VERSION ""

NS_ :

BS_:

BU_: DDE EGS Vector__XXX

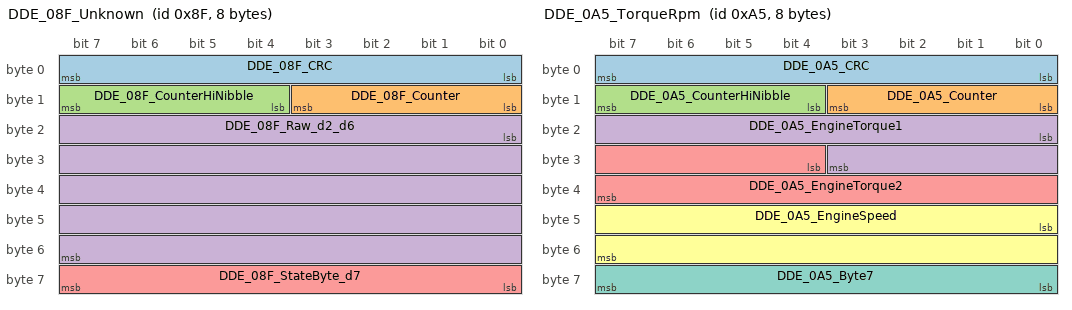
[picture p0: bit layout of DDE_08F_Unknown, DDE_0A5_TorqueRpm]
BO_ 143 DDE_08F_Unknown: 8 DDE
 SG_ DDE_08F_CRC : 0|8@1+ (1,0) [0|255] "" Vector__XXX
 SG_ DDE_08F_Counter : 8|4@1+ (1,0) [0|15] "" Vector__XXX
 SG_ DDE_08F_CounterHiNibble : 12|4@1+ (1,0) [0|15] "" Vector__XXX
 SG_ DDE_08F_Raw_d2_d6 : 16|40@1+ (1,0) [0|1099511627775] "" Vector__XXX
 SG_ DDE_08F_StateByte_d7 : 56|8@1+ (1,0) [0|255] "" Vector__XXX

BO_ 165 DDE_0A5_TorqueRpm: 8 DDE
 SG_ DDE_0A5_CRC : 0|8@1+ (1,0) [0|255] "" Vector__XXX
 SG_ DDE_0A5_Counter : 8|4@1+ (1,0) [0|15] "" Vector__XXX
 SG_ DDE_0A5_CounterHiNibble : 12|4@1+ (1,0) [0|15] "" Vector__XXX
 SG_ DDE_0A5_EngineTorque1 : 16|12@1+ (0.5,-1023.5) [-1023.5|1024] "Nm" Vector__XXX
 SG_ DDE_0A5_EngineTorque2 : 28|12@1+ (0.5,-1023.5) [-1023.5|1024] "Nm" Vector__XXX
 SG_ DDE_0A5_EngineSpeed : 40|16@1+ (0.25,0) [0|16383.75] "rpm" Vector__XXX
 SG_ DDE_0A5_Byte7 : 56|8@1+ (1,0) [0|255] "" Vector__XXX

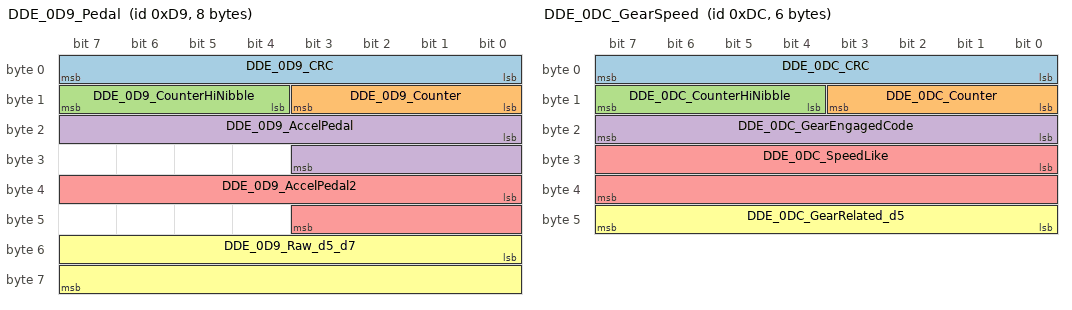
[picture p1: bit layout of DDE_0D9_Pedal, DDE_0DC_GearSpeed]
BO_ 217 DDE_0D9_Pedal: 8 DDE
 SG_ DDE_0D9_CRC : 0|8@1+ (1,0) [0|255] "" Vector__XXX
 SG_ DDE_0D9_Counter : 8|4@1+ (1,0) [0|15] "" Vector__XXX
 SG_ DDE_0D9_CounterHiNibble : 12|4@1+ (1,0) [0|15] "" Vector__XXX
 SG_ DDE_0D9_AccelPedal : 16|12@1+ (0.025,0) [0|102.375] "%" Vector__XXX
 SG_ DDE_0D9_AccelPedal2 : 32|12@1+ (0.025,0) [0|102.375] "%" Vector__XXX
 SG_ DDE_0D9_Raw_d5_d7 : 48|16@1+ (1,0) [0|65535] "" Vector__XXX

BO_ 220 DDE_0DC_GearSpeed: 6 DDE
 SG_ DDE_0DC_CRC : 0|8@1+ (1,0) [0|255] "" Vector__XXX
 SG_ DDE_0DC_Counter : 8|4@1+ (1,0) [0|15] "" Vector__XXX
 SG_ DDE_0DC_CounterHiNibble : 12|4@1+ (1,0) [0|15] "" Vector__XXX
 SG_ DDE_0DC_GearEngagedCode : 16|8@1+ (1,0) [0|255] "" Vector__XXX
 SG_ DDE_0DC_SpeedLike : 24|16@1+ (1,-2000) [-2000|63535] "raw" Vector__XXX
 SG_ DDE_0DC_GearRelated_d5 : 40|8@1+ (1,0) [0|255] "" Vector__XXX

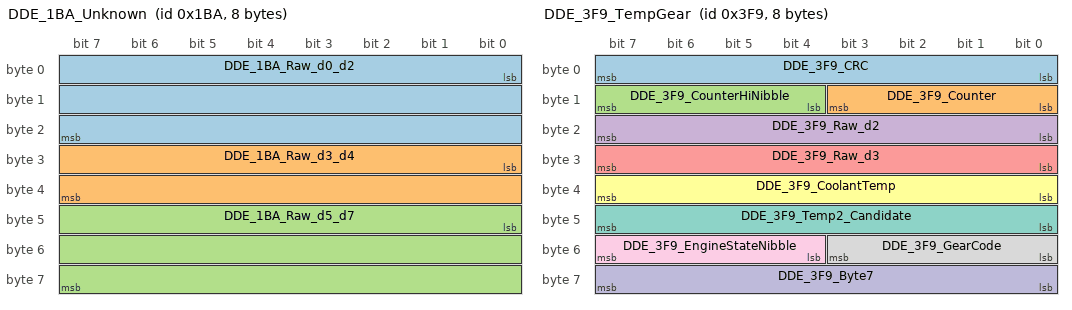
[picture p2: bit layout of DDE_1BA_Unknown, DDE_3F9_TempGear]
BO_ 442 DDE_1BA_Unknown: 8 DDE
 SG_ DDE_1BA_Raw_d0_d2 : 0|24@1+ (1,0) [0|16777215] "" Vector__XXX
 SG_ DDE_1BA_Raw_d3_d4 : 24|16@1+ (1,0) [0|65535] "" Vector__XXX
 SG_ DDE_1BA_Raw_d5_d7 : 40|24@1+ (1,0) [0|16777215] "" Vector__XXX

BO_ 1017 DDE_3F9_TempGear: 8 DDE
 SG_ DDE_3F9_CRC : 0|8@1+ (1,0) [0|255] "" Vector__XXX
 SG_ DDE_3F9_Counter : 8|4@1+ (1,0) [0|15] "" Vector__XXX
 SG_ DDE_3F9_CounterHiNibble : 12|4@1+ (1,0) [0|15] "" Vector__XXX
 SG_ DDE_3F9_Raw_d2 : 16|8@1+ (1,0) [0|255] "" Vector__XXX
 SG_ DDE_3F9_Raw_d3 : 24|8@1+ (1,0) [0|255] "" Vector__XXX
 SG_ DDE_3F9_CoolantTemp : 32|8@1+ (1,-48) [-48|207] "degC" Vector__XXX
 SG_ DDE_3F9_Temp2_Candidate : 40|8@1+ (1,-48) [-48|207] "degC" Vector__XXX
 SG_ DDE_3F9_GearCode : 48|4@1+ (1,0) [0|15] "" Vector__XXX
 SG_ DDE_3F9_EngineStateNibble : 52|4@1+ (1,0) [0|15] "" Vector__XXX
 SG_ DDE_3F9_Byte7 : 56|8@1+ (1,0) [0|255] "" Vector__XXX

BO_ 1298 DDE_512_NM: 8 DDE
 SG_ DDE_512_Raw_d0_d6 : 0|56@1+ (1,0) [0|72057594037927935] "" Vector__XXX
 SG_ DDE_512_NodeAddress : 56|8@1+ (1,0) [0|255] "" Vector__XXX

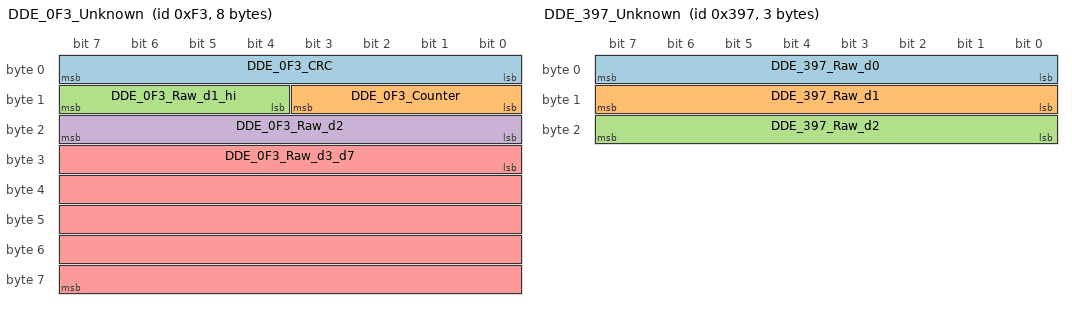
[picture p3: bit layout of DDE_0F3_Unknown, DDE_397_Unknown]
BO_ 243 DDE_0F3_Unknown: 8 DDE
 SG_ DDE_0F3_CRC : 0|8@1+ (1,0) [0|255] "" Vector__XXX
 SG_ DDE_0F3_Counter : 8|4@1+ (1,0) [0|15] "" Vector__XXX
 SG_ DDE_0F3_Raw_d1_hi : 12|4@1+ (1,0) [0|15] "" Vector__XXX
 SG_ DDE_0F3_Raw_d2 : 16|8@1+ (1,0) [0|255] "" Vector__XXX
 SG_ DDE_0F3_Raw_d3_d7 : 24|40@1+ (1,0) [0|1099511627775] "" Vector__XXX

BO_ 311 DDE_137_Unknown: 2 DDE
 SG_ DDE_137_Raw_d0 : 0|8@1+ (1,0) [0|255] "" Vector__XXX
 SG_ DDE_137_Raw_d1 : 8|8@1+ (1,0) [0|255] "" Vector__XXX

BO_ 919 DDE_397_Unknown: 3 DDE
 SG_ DDE_397_Raw_d0 : 0|8@1+ (1,0) [0|255] "" Vector__XXX
 SG_ DDE_397_Raw_d1 : 8|8@1+ (1,0) [0|255] "" Vector__XXX
 SG_ DDE_397_Raw_d2 : 16|8@1+ (1,0) [0|255] "" Vector__XXX

BO_ 947 DDE_3B3_Unknown: 7 DDE
 SG_ DDE_3B3_Raw : 0|56@1+ (1,0) [0|72057594037927935] "" Vector__XXX

BO_ 441 DDE_1B9_Unknown: 2 DDE
 SG_ DDE_1B9_Raw_d0 : 0|8@1+ (1,0) [0|255] "" Vector__XXX
 SG_ DDE_1B9_Raw_d1 : 8|8@1+ (1,0) [0|255] "" Vector__XXX

BO_ 708 DDE_2C4_Unknown: 8 DDE
 SG_ DDE_2C4_Raw_d0_d1 : 0|16@1+ (1,0) [0|65535] "" Vector__XXX
 SG_ DDE_2C4_Raw_d2_d7 : 16|48@1+ (1,0) [0|281474976710655] "" Vector__XXX

BO_ 1426 DDE_592_ServiceChannel: 8 DDE
 SG_ DDE_592_Byte0 : 0|8@1+ (1,0) [0|255] "" Vector__XXX
 SG_ DDE_592_Payload : 8|56@1+ (1,0) [0|72057594037927935] "" Vector__XXX

BO_ 641 DDE_281_Voltage: 2 DDE
 SG_ DDE_281_SupplyVoltage : 0|12@1+ (0.015,0) [0|61.425] "V" Vector__XXX
 SG_ DDE_281_Raw_d1_hi : 12|4@1+ (1,0) [0|15] "" Vector__XXX

BO_ 1019 DDE_3FB_Unknown: 6 DDE
 SG_ DDE_3FB_Raw_d0 : 0|8@1+ (1,0) [0|255] "" Vector__XXX
 SG_ DDE_3FB_Raw_d1_d5 : 8|40@1+ (1,0) [0|1099511627775] "" Vector__XXX

CM_ "BMW F11 520d (DDE EDC17C50) PT-CAN (logged as bus 3). Transmitter DDE. Built by Fred 2026-10-30 from captures ptcan1 (ignonoff, 3krev, r10md10m drive) and bench_f10 (F10 DDE alone). Byte d0 = first CAN data byte. Only signals with evidence are named; undecoded bytes are Raw_*. Cycle times are from the F11 car where present. See README.md.";
CM_ SG_ 143 DDE_08F_CRC "E2E CRC8 poly 0x1D init 0x00 xorout 0x00 over d1..d7, then XOR K=0x3C. Confirmed (see f11_dde_e2e.md).";
CM_ SG_ 143 DDE_08F_Counter "Alive counter, low nibble of d1, 0..14 (15 never used), +1 per frame, starts at 1 each wake. Confirmed.";
CM_ SG_ 143 DDE_08F_CounterHiNibble "High nibble of d1. Fixed 0x1 (0x3 briefly at crank). It is inside the CRC span, so reproduce it exactly.";
CM_ SG_ 143 DDE_08F_Raw_d2_d6 "Not decoded. LE pairs sit near 0x7D00 / 0x7CF9 in P and move in R/D.";
CM_ SG_ 143 DDE_08F_StateByte_d7 "Quasi-static enum (0x80, 0x10, 0xC0 seen). Meaning unknown.";
CM_ BO_ 143 "DDE-generated (confirmed: bench + car). Same layout and K as FlexRay 0x29 c3 group 1. On F11 PT-CAN at ~30 ms (33 Hz); PT-CAN2 10 ms. E2E K=0x3C, span d1..d7. Payload not decoded: it changes only with R/D engaged (meaning unknown).";
CM_ SG_ 165 DDE_0A5_CRC "E2E CRC8 poly 0x1D init 0x00 xorout 0x00 over d1..d7, then XOR K=0x6A. Confirmed (see f11_dde_e2e.md).";
CM_ SG_ 165 DDE_0A5_Counter "Alive counter, low nibble of d1, 0..14 (15 never used), +1 per frame, starts at 1 each wake. Confirmed.";
CM_ SG_ 165 DDE_0A5_CounterHiNibble "High nibble of d1. Fixed 0xF in the F11 car; 0xD on the F10 bench DDE. It is inside the CRC span, so reproduce it exactly.";
CM_ SG_ 165 DDE_0A5_EngineTorque1 "bits16..27. Equal to FlexRay 0x28 c1 torque field (r 0.999, slope 1.0). Scale/offset from a public hint; behaviour plausible (~232 at crank, 25..50 at idle, -35 engine off) but there is no independent torque label. Confidence: high (field), hint (unit).";
CM_ SG_ 165 DDE_0A5_EngineTorque2 "bits28..39, same format as torque 1. Role unknown. Confidence: medium.";
CM_ SG_ 165 DDE_0A5_EngineSpeed "d5..d6 LE /4. Confirmed: equal to FlexRay 0x28 c1 rpm (r 1.000), which matches OBD PID 0x0C (r 0.9998, runs 1 and 2).";
CM_ SG_ 165 DDE_0A5_Byte7 "Constant 0xF1 in all logs; inside the CRC span.";
CM_ BO_ 165 "DDE-generated (confirmed: F10 DDE-alone bench + F11 car). Same layout and K as DDE FlexRay 0x28 c1 group 1 (payload bytes 0..7), but its counters run independently of FlexRay. On F11 PT-CAN (bus 3) at 20 ms; on PT-CAN2 at 10 ms. E2E K=0x6A, span d1..d7.";
CM_ SG_ 217 DDE_0D9_CRC "E2E CRC8 poly 0x1D init 0x00 xorout 0x00 over d1..d7, then XOR K=0xD7. Confirmed (see f11_dde_e2e.md).";
CM_ SG_ 217 DDE_0D9_Counter "Alive counter, low nibble of d1, 0..14 (15 never used), +1 per frame, starts at 1 each wake. Confirmed.";
CM_ SG_ 217 DDE_0D9_CounterHiNibble "High nibble of d1. Fixed 0x1 (0x3 for ~60..80 ms at crank). It is inside the CRC span, so reproduce it exactly.";
CM_ SG_ 217 DDE_0D9_AccelPedal "bits16..27 /40. Equal to FlexRay 0x28 c1 pedal field (r 0.9998, slope 1.001). Scale from a public hint; 0 at rest, rises on throttle blips. No OBD pedal PID was logged. Confidence: high (field), hint (scale).";
CM_ SG_ 217 DDE_0D9_AccelPedal2 "bits32..43, second pedal/throttle-like value (r 0.989). Confidence: medium.";
CM_ SG_ 217 DDE_0D9_Raw_d5_d7 "Not decoded (ign-on constant e0 7f / c0 in d7).";
CM_ BO_ 217 "DDE-generated (confirmed: bench + car). Same layout and K as FlexRay 0x28 c1 group 2 (payload bytes 8..15). On F11 PT-CAN (bus 3) at 20 ms; on PT-CAN2 at 10 ms. E2E K=0xD7, span d1..d7.";
CM_ SG_ 220 DDE_0DC_CRC "E2E CRC8 poly 0x1D init 0x00 xorout 0x00 over d1..d5, then XOR K=0x0F. Confirmed (see f11_dde_e2e.md).";
CM_ SG_ 220 DDE_0DC_Counter "Alive counter, low nibble of d1, 0..14 (15 never used), +1 per frame, starts at 1 each wake. Confirmed.";
CM_ SG_ 220 DDE_0DC_CounterHiNibble "High nibble of d1. Fixed 0x1 (0x3 briefly at crank). It is inside the CRC span, so reproduce it exactly.";
CM_ SG_ 220 DDE_0DC_GearEngagedCode "d2: 0x22 = P, 0x25 = R, 0x24 = D (wake sequence 0x80 -> 0x20 -> 0x22). Confirmed against EGS 0x3FD (drive log).";
CM_ SG_ 220 DDE_0DC_SpeedLike "d3..d4 LE - 2000. Speed-like: r 0.998 vs vehicle speed 0x1A1, fitted ~7.67 raw per km/h, unsigned (positive in R). Physical unit unknown (could be a shaft speed). Confidence: medium-high.";
CM_ SG_ 220 DDE_0DC_GearRelated_d5 "d5: 0xFE in P, 0xF4 in R/D, 0xFC during park request. Confidence: medium. Inside CRC span.";
CM_ BO_ 220 "DDE-generated (confirmed: bench + car). PT-CAN only (not on PT-CAN2). Same layout and K as FlexRay 0x28 c3 group 2 (payload bytes 8..13). E2E K=0x0F, span d1..d5.";
CM_ SG_ 442 DDE_1BA_Raw_d0_d2 "Not decoded (00 00 00 at ign-on, vary when running).";
CM_ SG_ 442 DDE_1BA_Raw_d3_d4 "Not decoded LE16.";
CM_ SG_ 442 DDE_1BA_Raw_d5_d7 "Mostly constant F3 5A F0.";
CM_ BO_ 442 "DDE: sent by the F10 DDE alone on the bench, and in the F11 car its payload is identical to DDE FlexRay 0xE8 L9. Rate on bench ~1 s. CAVEAT: in the F11 car logs 0x1BA appears ONLY on PT-CAN2 (bus 2), never on PT-CAN (bus 3); it is in this file because it was requested and the bench saw it. Which physical bus the bench was wired to is not recorded beyond bus 0. No CRC/counter. Not decoded: d3..d4 LE16 varies continuously after ~5 s (ign-on value 0x2710).";
CM_ SG_ 1017 DDE_3F9_CRC "E2E CRC8 poly 0x1D init 0x00 xorout 0x00 over d1..d7, then XOR K=0x04. Confirmed (see f11_dde_e2e.md).";
CM_ SG_ 1017 DDE_3F9_Counter "Alive counter, low nibble of d1, 0..14 (15 never used), +1 per frame, starts at 1 each wake. Confirmed.";
CM_ SG_ 1017 DDE_3F9_CounterHiNibble "High nibble of d1. Fixed 0x1 (0x3 briefly at crank). Counter steps per transmission, not per time. It is inside the CRC span, so reproduce it exactly.";
CM_ SG_ 1017 DDE_3F9_Raw_d2 "Not decoded (0x80 / 0x82 seen).";
CM_ SG_ 1017 DDE_3F9_Raw_d3 "Not decoded.";
CM_ SG_ 1017 DDE_3F9_CoolantTemp "d4 - 48. Confirmed: equals FlexRay 0xE6 payload byte 4, which matches OBD PID 0x05 (r 0.997, 89.5 % exact, run 1).";
CM_ SG_ 1017 DDE_3F9_Temp2_Candidate "CANDIDATE. d5 - 48. A public hint calls it oil temperature. OBD shows it is NOT coolant (slower, lags). No independent label.";
CM_ SG_ 1017 DDE_3F9_GearCode "Low nibble of d6: 3 = P, 2 = R, 5 = D, 1 = park requested while in D. Confirmed against EGS 0x3FD gear display (drive log). N was not captured.";
CM_ SG_ 1017 DDE_3F9_EngineStateNibble "High nibble of d6: 2 = ign-on before crank, 1 = crank / after stop, 0 = running. Confidence: medium (ts run 4 and ptcan1 agree; inference from timing).";
CM_ SG_ 1017 DDE_3F9_Byte7 "Constant 0x47 in the F11 car.";
CM_ BO_ 1017 "DDE-generated (confirmed: bench + car). Same PDU as FlexRay 0xE6 L9 (same K). ~1 s plus extra frames on change. On both PT-CAN and PT-CAN2 with identical payloads. E2E K=0x04, span d1..d7.";
CM_ SG_ 1298 DDE_512_Raw_d0_d6 "Constant 00 00 00 00 FF FF 00.";
CM_ SG_ 1298 DDE_512_NodeAddress "0x12 = DDE.";
CM_ BO_ 1298 "BMW network-management frame, node 0x12 = DDE. Confirmed (bench + car, both PT-CAN and PT-CAN2). Payload 00 00 00 00 FF FF 00 12 constant in all logs. Same content as the DDE share of FlexRay 0x5C.";
CM_ SG_ 243 DDE_0F3_CRC "E2E CRC8 poly 0x1D init 0x00 xorout 0x00 over d1..d7, then XOR K=0x8F. Confirmed (see f11_dde_e2e.md).";
CM_ SG_ 243 DDE_0F3_Counter "Alive counter, low nibble of d1, 0..14 (15 never used), +1 per frame, starts at 1 each wake. Confirmed.";
CM_ SG_ 243 DDE_0F3_Raw_d1_hi "High nibble of d1 is NOT fixed (0 engine off; 0xD/0xE seen while running) - data, not part of the counter. Inside CRC span.";
CM_ SG_ 243 DDE_0F3_Raw_d2 "CANDIDATE: roughly rpm/160 (values 4..5 at idle). Not validated.";
CM_ SG_ 243 DDE_0F3_Raw_d3_d7 "Constant C0 F0 FF FF FF in the car (bench: C0 F0 C0 FF FF).";
CM_ BO_ 243 "DDE-generated (confirmed: F10 DDE-alone bench). F11: PT-CAN only, 20 ms. E2E K=0x8F, span d1..d7. Payload mostly undecoded.";
CM_ SG_ 311 DDE_137_Raw_d0 "Not decoded.";
CM_ SG_ 311 DDE_137_Raw_d1 "Not decoded; 00 engine off, non-zero while running.";
CM_ BO_ 311 "Sent by the F10 DDE alone on the bench (10 ms). CAVEAT: in the F11 car logs 0x137 appears ONLY on PT-CAN2 (bus 2), never on PT-CAN (bus 3). Not decoded: d0 FD (FD/FC seen), d1 00 with engine off, other values (high nibble 0xC) while running.";
CM_ SG_ 919 DDE_397_Raw_d0 "Not decoded (C0 engine off).";
CM_ SG_ 919 DDE_397_Raw_d1 "Not decoded.";
CM_ SG_ 919 DDE_397_Raw_d2 "Not decoded; earlier analysis saw torque-like behaviour (low confidence).";
CM_ BO_ 919 "DDE-generated (confirmed: F10 bench). F11: on both PT-CAN and PT-CAN2 with identical payloads, ~60 ms (irregular, 0.5..1 s with engine off). No CRC found. Public EGS fault text names 0x397 diagnosis OBD engine, sent by DME/DDE and received by the EGS (hint only).";
CM_ SG_ 947 DDE_3B3_Raw "Not decoded.";
CM_ BO_ 947 "DDE-generated (confirmed: F10 bench). F11: on both PT-CAN and PT-CAN2 with identical payloads; irregular (median 160 ms, gaps up to 5 s). No CRC found. Not decoded.";
CM_ SG_ 441 DDE_1B9_Raw_d0 "Not decoded (00 at rest, a few values while running).";
CM_ SG_ 441 DDE_1B9_Raw_d1 "Constant FF.";
CM_ BO_ 441 "DDE-generated (confirmed: F10 bench). F11: PT-CAN only, 1 s. CAVEAT: DLC 2 in the F11 car (00 FF) but DLC 4 on the F10 bench (00 FF C8 FF). Not decoded.";
CM_ SG_ 708 DDE_2C4_Raw_d0_d1 "Not decoded; 00 00 with engine off, varies while running.";
CM_ SG_ 708 DDE_2C4_Raw_d2_d7 "Constant FF 64 64 64 0x F0 (d6 00 car / 01 bench).";
CM_ BO_ 708 "DDE-generated (confirmed: F10 bench). F11: PT-CAN only, 100 ms. No CRC found. Not decoded.";
CM_ SG_ 1426 DDE_592_Byte0 "Address-like prefix (0x26, 0x30, 0x32, 0x40, 0x80, 0x85 seen). Meaning not confirmed.";
CM_ SG_ 1426 DDE_592_Payload "Raw payload (ISO-TP style PCI in d1 for the multi-frame messages). Not decoded.";
CM_ BO_ 1426 "DDE service channel (BMW 0x580 + sender address 0x12; the F10 bench DDE also sent 0x592). Event-driven, no cycle. Mostly short status frames (26 85 F5 ..; 30 01 ..; 32 01 ..; 40 22 00 15 ..). At every ignition-on it sends a 3-frame ISO-TP-style message 80 10 11 | 10 + 16 random bytes on PT-CAN, answered by 0x5C0 (CAS/FEM, address assumed) with 7 bytes 21 + 6 random bytes. Random content differs every wake: IMMOBILISER (EWS) HANDSHAKE CANDIDATE, ALGORITHM AND KEY UNKNOWN; replay is not expected to work. On PT-CAN2 the DDE also answers the EGS 0x598 challenge (see the PT-CAN2 DBC).";
CM_ SG_ 641 DDE_281_SupplyVoltage "(d0 + (d1 & 0x0F) * 256) * 15 mV. Tracks the DDE FlexRay 0xFB L7 voltage (OBD PID 0x42 confirmed) with r 0.970 (drive) / 0.919 (3krev), slope ~0.95. Confidence: medium (scale fitted, not exact).";
CM_ SG_ 641 DDE_281_Raw_d1_hi "Constant 0xF.";
CM_ BO_ 641 "DDE-generated per the F10 DDE-alone bench (earlier vehicle-side attribution as a vehicle voltage message is superseded). F11: PT-CAN only, 100 ms.";
CM_ SG_ 1019 DDE_3FB_Raw_d0 "Constant per unit (CD car, BE bench).";
CM_ SG_ 1019 DDE_3FB_Raw_d1_d5 "Not decoded; d1 and d5 vary.";
CM_ BO_ 1019 "CONFLICTING ATTRIBUTION. The F10 DDE alone on the bench sends 0x3FB (60 ms), so the DDE can be a sender. Earlier F11 analysis found 0x3FB content equal to vehicle FlexRay 0xE9 L7 with CAN ~7 ms later (looked like a gateway copy). F11: both PT-CAN and PT-CAN2, identical payloads, ~60 ms. d0 is 0xCD in the car, 0xBE on the bench. Owner on the F11 not settled. Not decoded.";

BA_DEF_ BO_ "GenMsgCycleTime" INT 0 65535;
BA_DEF_DEF_ "GenMsgCycleTime" 0;
BA_ "GenMsgCycleTime" BO_ 143 30;
BA_ "GenMsgCycleTime" BO_ 165 20;
BA_ "GenMsgCycleTime" BO_ 217 20;
BA_ "GenMsgCycleTime" BO_ 220 20;
BA_ "GenMsgCycleTime" BO_ 442 1000;
BA_ "GenMsgCycleTime" BO_ 1017 1000;
BA_ "GenMsgCycleTime" BO_ 1298 640;
BA_ "GenMsgCycleTime" BO_ 243 20;
BA_ "GenMsgCycleTime" BO_ 311 10;
BA_ "GenMsgCycleTime" BO_ 919 60;
BA_ "GenMsgCycleTime" BO_ 947 160;
BA_ "GenMsgCycleTime" BO_ 441 1000;
BA_ "GenMsgCycleTime" BO_ 708 100;
BA_ "GenMsgCycleTime" BO_ 641 100;
BA_ "GenMsgCycleTime" BO_ 1019 60;

VAL_ 220 DDE_0DC_GearEngagedCode 34 "P" 36 "D" 37 "R" ;
VAL_ 1017 DDE_3F9_GearCode 1 "Park requested (in D)" 2 "R" 3 "P" 5 "D" ;
